# M05x_registers register map
File version: 0.1
M05x_registers Microcontroller dummy device
CPU: 
Registers are 32-bit, read-write, reset 0x0 unless marked. A register's access mark holds for its fields unless they carry their own. Offsets are from the block's base; lines under a group give offsets from that group; [hi:lo] are bit positions; {n}, {i} and the like mark numbered series; 'fields as' and 'values as' point back to an identical list; <NAME> marks a mode.

## Memory map
0x40004000 WDT size 0x4 — Registers group
0x40010000 TMR0 size 0x10 — Registers group
0x40010020 TMR1 size 0x10 — Registers group
0x40020000 I2C size 0x34 — Registers group
0x40030000 SPI0 size 0xC — Registers group
0x40034000 SPI1 size 0xC — Registers group
0x40040000 PWMA size 0x3C — Registers group
0x40050000 UART0 size 0x34 — Registers group
0x400E0000 ADC size 0x38 — Registers group
0x40110000 TMR2 size 0x10 — Registers group
0x40110020 TMR3 size 0x10 — Registers group
0x40140000 PWMB size 0x3C — Registers group
0x40150000 UART1 size 0x34 — Registers group
0x50000000 GCR size 0x10 — Registers group
0x50000200 CLK size 0x28 — Registers group
0x50000300 INT size 0x40 — Registers group
0x50004000 GP0 size 0x24 — Registers group
0x50004040 GP1 size 0x24 — Registers group
0x50004080 GP2 size 0x24 — Registers group
0x500040C0 GP3 size 0x24 — Registers group
0x50004100 GP4 size 0x24 — Registers group
0x50004180 GPIO size 0x4 — Registers group
0x50004200 GP0_BITS blocks up to offset 0x220 — Registers group
0x50004220 GP1_BITS blocks up to offset 0x220 — Registers group
0x50004240 GP2_BITS blocks up to offset 0x220 — Registers group
0x50004260 GP3_BITS blocks up to offset 0x220 — Registers group
0x50004280 GP4_BITS blocks up to offset 0x220 — Registers group
0x5000C000 FMC size 0x1C — Registers group
0x50010000 EBI_CTL size 0x8 — Registers group
0xE000E000 SCS blocks up to offset 0x1C — Registers group

## EBI_CTL — Registers group
Base 0x50010000
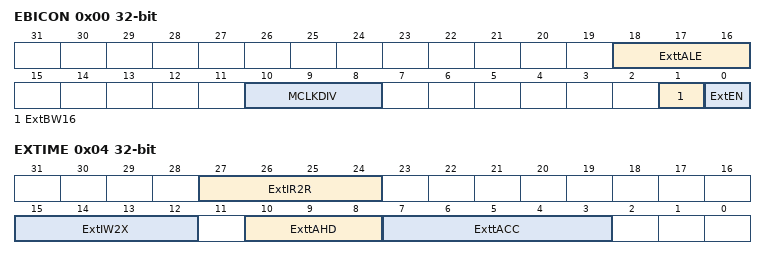
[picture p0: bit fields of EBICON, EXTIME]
0x00 EBICON — External Bus Interface General Control Register
  [18:16] ExttALE — Expand Time of ALE The ALE width (tALE) to latch the address can be controlled by ExttALE. tALE = (ExttALE + 1) * MCLK
  [10:8] MCLKDIV — External Output Clock Divider The frequency of EBI output clock is controlled by MCLKDIV. MCLKDIV Output clock (MCLK) 000 HCLK/1 001 HCLK/2 010 HCLK/4 011 HCLK/8 100 HCLK/16 101 HCKL/32 11X default Notice: Default value of output clock is HCLK/1
  [1] ExtBW16 — EBI data width 16 bit This bit defines if the data bus is 8-bit or 16-bit. 0 = EBI data width is 8 bit 1 = EBI data width is 16 bit
  [0] ExtEN — EBI Enable This bit is the functional enable bit for EBI. 0 = EBI function is disabled 1 = EBI function is enabled
0x04 EXTIME — External Bus Interface 0 Timing Control Register
  [27:24] ExtIR2R — Idle State Cycle Between Read-Read When read action is finish and next action is going to read, idle state is inserted and nCS return to high if ExtIR2R is not zero. Idle state cycle = (ExtIR2R * MCLK)
  [15:12] ExtIW2X — Idle State Cycle After Write When write action is finish, idle state is inserted and nCS return to high if ExtIW2X is not zero. Idle state cycle = (ExtIW2X * MCLK)
  [10:8] ExttAHD — EBI Data Access Hold Time ExttAHD define data access hold time (tAHD). tAHD = (ExttAHD + 1) * MCLK
  [7:3] ExttACC — EBI Data Accesss Time ExttACC define data access time (tACC). tACC = (ExttACC + 1) * MCLK

## FMC — Registers group
Base 0x5000C000
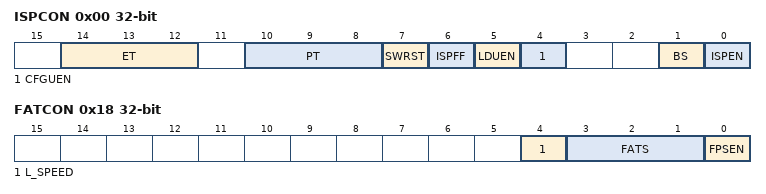
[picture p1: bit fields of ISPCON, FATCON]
0x00 ISPCON — ISP Control Register
  [14:12] ET — Flash Erase Time ET[2] ET[1] ET[0] Erase Time (ms) 0 0 0 20 (default) 0 0 1 25 0 1 0 30 0 1 1 35 1 0 0 3 1 0 1 5 1 1 0 10 1 1 1 15
  [10:8] PT — Flash Program Time PT[2] PT[1] PT[0] Program Time (us) 0 0 0 40 0 0 1 45 0 1 0 50 0 1 1 55 1 0 0 20 1 0 1 25 1 1 0 30 1 1 1 35
  [7] SWRST — Software Reset Writing 1 to this bit to start software reset. It is cleared by hardware after reset is finished.
  [6] ISPFF write-1-clears — ISP Fail Flag This bit is set by hardware when a triggered ISP meets any of the following conditions: (1) APROM writes to itself. (2) LDROM writes to itself. (3) Destination address is illegal, such as over an available range. Write 1 to clear.
  [5] LDUEN — LDROM Update Enable LDROM update enable bit. 1 = LDROM can be updated when the MCU runs in APROM. 0 = LDROM cannot be updated
  [4] CFGUEN — Config Update Enable Writing this bit to 1 enables s/w to update Config value by ISP procedure regardless of program code is running in APROM or LDROM. 1 = Config update enable 0 = Config update disable
  [1] BS — Boot Select This bit is protected bit. Set/clear this bit to select next booting from LDROM/APROM, respectively. This bit also functions as MCU booting status flag, which can be used to check where MCU booted from. This bit is initiated with the inversed value of CBS in Config0 after power-on reset; It keeps the same value at other reset. 1 = boot from LDROM 0 = boot from APROM
  [0] ISPEN — ISP Enable This bit is protected bit. ISP function enable bit. Set this bit to enable ISP function. 1 = Enable ISP function 0 = Disable ISP function
0x04 ISPADR — ISP Address Register
  [31:0] ISPADR — ISP Address NuMicro M051 series equips with a maximum 16kx32 embedded flash, it supports word program only. ISPARD[1:0] must be kept 2'b00 for ISP operation.
0x08 ISPDAT — ISP Data Register
  [31:0] ISPDAT — ISP Data Write data to this register before ISP program operation Read data from this register after ISP read operation
0x0C ISPCMD — ISP Command Register
  [5:0] FOEN_FCEN_FCTRL — ISP Command ISP command table is shown below: Operation Mode FOEN FCEN FCTRL[3:0] Read 0 0 0 0 0 0 Program 1 0 0 0 0 1 Page Erase 1 0 0 0 1 0
0x10 ISPTRG — ISP Trigger Control Register
  [0] ISPGO — ISP start trigger Write 1 to start ISP operation and this bit will be cleared to 0 by hardware automatically when ISP operation is finish. 1 = ISP is on going 0 = ISP done
0x14 DFBADR ro reset 0x1F000 — Data Flash Base Address
  [31:0] DFBA — Data Flash Base Address This register indicates data flash start address. It is a read only register. For 8/16/32/64kB flash memory device, the data flash size is 4kB and it start address is fixed at 0x01F000 by hardware internally.
0x18 FATCON — Flash Access Time Control Register
  [4] L_SPEED — Flash Low Speed Mode Enable 1 = Flash access always no wait state (zero wait state) 0 = Insert wait state while Flash access discontinued address. Note: Set this bit only when HCLK <= 25MHz. If HCLK > 25MHz, CPU will fetch wrong code and cause fail result.
  [3:1] FATS — Flash Access Time Window Select These bits are used to decide flash sense amplifier active duration. FATS Access Time window (ns) 000 40 001 50 010 60 011 70 100 80 101 90 110 100 111 Reserved
  [0] FPSEN — Flash Power Save Enable If CPU clock is slower than 24 MHz, then s/w can enable flash power saving function. 1 = Enable flash power saving 0 = Disable flash power saving
